# cslr_dev register map
Vendor: Texas Instruments
Peripheral module from a debugger description file.
Registers are 32-bit, access not given, reset 0x0 unless marked. A register's access mark holds for its fields unless they carry their own. Offsets are as the file gives them; lines under a group give offsets from that group; [hi:lo] are bit positions; {n}, {i} and the like mark numbered series; 'fields as' and 'values as' point back to an identical list; <NAME> marks a mode.

## DEV — Device Registers on the SOC
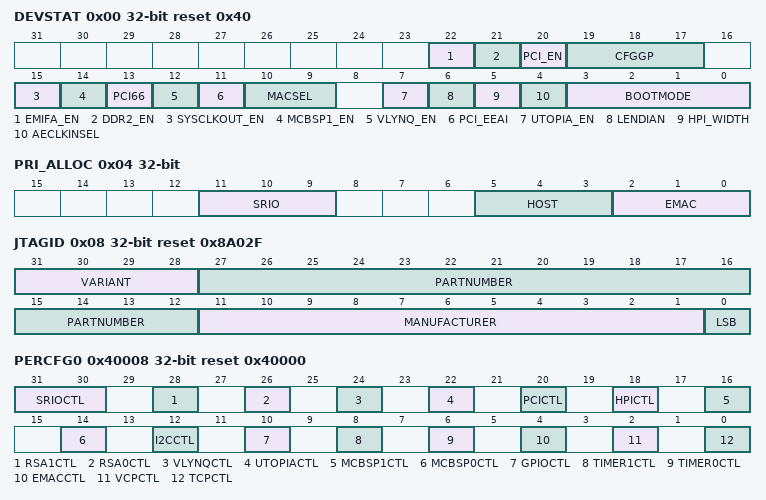
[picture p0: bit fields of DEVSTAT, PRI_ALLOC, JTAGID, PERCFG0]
0x00 DEVSTAT reset 0x40 — Device Status Register
  [22] EMIFA_EN ro — EMIFA Enable Status
    0=DISABLE; 1=ENABLE
  [21] DDR2_EN ro — DDR2 Enable Status
    0=DISABLE; 1=ENABLE
  [20] PCI_EN ro — PCI Enable Status
    0=HPI (HPI is enabled); 1=PCI (PCI is enabled)
  [19:17] CFGGP ro — Used as general purpose input for configuration
  [15] SYSCLKOUT_EN ro — Sysclkout enable status
    0=GP1 (GP[1] pin function of the SYSCLK4/GP[1] pin enabled (default).); 1=SYSCLK4 (SYSCLK4 pin function of the SYSCLK4/GP[1] pin enabled.)
  [14] MCBSP1_EN ro — McBSP1 enable status bits
    0=GPIO (GPIO pin functions enabled (default).); 1=MCBSP_1 (McBSP1 pin functions enabled.)
  [13] PCI66 ro — PCI Frequency Selection (PCI66) status bit
    0=33MHZ (33 MHz operating frequency); 1=66MHZ (66MHz operating frequency)
  [12] VLYNQ_EN ro — VLYNQ Enable (VLYNQ_EN) status bit, Shows the status of whether the VLYNQ peripheral or McBSP1, McBSP0, GPIO peripherals are enabled/disabled.
    0=DISABLE (Vlynq disabled, Mcbsp0,Mcbsp1, gpio enabled); 1=ENABLE (Vlynq enabled, Mcbsp0,Mcbsp1, gpio disabled)
  [11] PCI_EEAI ro — PCI EEPROM Auto-Initialization (PCI_EEAI) status bit.Shows whether the PCI auto-initialization via external EEPROM is enabled/disabled.
    0=DISABLE (PCI auto-initialization through external EEPROM is disabled; the PCI peripheral uses the specified); 1=ENABLE (PCI auto-initialization through external EEPROM is enabled; the PCI peripheral is configured through external I2C EEPROM provided the PCI peripheral pin is enabled (PCI_EN = 1).)
  [10:9] MACSEL ro — MACSEL[1:0] EMAC Interface Select (MACSEL[1:0]) status bits. Shows which EMAC interface mode has been selected.
    0=MII (10/100 EMAC/MDIO with MII Interface); 1=RMII (10/100 EMAC/MDIO with RMII Interface); 2=GMII (10/100/1000 EMAC/MDIO with GMII Interface); 3=RGMII (10/100/1000 EMAC/MDIO with RGMII Mode Interface)
  [7] UTOPIA_EN ro — UTOPIA enable status bit
    0=DISABLE (UTOPIA disabled); 1=ENABLE (UTOPIA enabled)
  [6] LENDIAN ro — Device Endian Mode
    0=BE (System is operating in Big Endian Mode); 1=LE (System is operating in Little Endian Mode)
  [5] HPI_WIDTH ro — HPI bus width control bit
    0=16BIT (HPI operating in 16-bit mode); 1=32BIT (HPI operating in 32-bit mode)
  [4] AECLKINSEL ro — EMIFA input clock select
    0=AECLKIN; 1=SYSCLK3 (The SYSCLK3 clock rate is software selectable via the software PLL1 controller. By default, SYSCLK3 is selected as CPU/8 clock rate.)
  [3:0] BOOTMODE ro — Bootmode configuration bits
    0=NONE (No Boot); 1=HPI_PCI (HPI/PCI Boot); 2=EMIFA64BIT (EMIFA 64-bit fast boot); 4=EMIFA8BIT (EMIFA 8-bit ROM boot); 5=I2C (I2C boot); 6=UTOPIA (Utopia boot); 7=EMAC (Emac boot); 9=SRIO (Rapid I/O boot)
0x04 PRI_ALLOC — Priority Allocation Register
  [11:9] SRIO — SRIO Descriptor
  [5:3] HOST — Host Priority
  [2:0] EMAC — Emac Priority
0x08 JTAGID ro reset 0x8A02F — JTAG and BSDL Identification register
  [31:28] VARIANT, [27:12] PARTNUMBER, [11:1] MANUFACTURER, [0] LSB
0x40004 PERLOCK wo reset 0xF0F0F0F0 — Peripheral lock register
  [31:0] LOCKVAL — When programmed with 0xF0A0B00 allows one write to one of PERCFG0 16 SYSCLK2 cycles.
    0xF0A0B00=UNLOCK
0x40008 PERCFG0 reset 0x40000 — Peripheral Configuration register
  [31:30] SRIOCTL wo — Mode control for SRIO
    0=DISABLE; 3=ENABLE
  [28] RSA1CTL wo — Mode control for RSA1
    0=DISABLE; 1=ENABLE
  [26] RSA0CTL wo — Mode control for RSA0
    0=DISABLE; 1=ENABLE
  [24] VLYNQCTL wo — Mode control for VLYNQ
    0=DISABLE; 1=ENABLE
  [22] UTOPIACTL wo — Mode control for UTOPIA
    0=DISABLE; 1=ENABLE
  [20] PCICTL wo — Mode control for PCI
    0=DISABLE; 1=ENABLE
  [18] HPICTL wo — Mode control for HPI
    0=DISABLE; 1=ENABLE
  [16] MCBSP1CTL wo — Mode control for MCBSP1
    0=DISABLE; 1=ENABLE
  [14] MCBSP0CTL wo — Mode control for MCBSP0
    0=DISABLE; 1=ENABLE
  [12] I2CCTL wo — Mode control for I2C
    0=DISABLE; 1=ENABLE
  [10] GPIOCTL wo — Mode control for GPIO
    0=DISABLE; 1=ENABLE
  [8] TIMER1CTL wo — Mode control for Timer1
    0=DISABLE; 1=ENABLE
  [6] TIMER0CTL wo — Mode control for Timer0
    0=DISABLE; 1=ENABLE
  [4] EMACCTL wo — Mode control for EMAC
    0=DISABLE; 1=ENABLE
  [2] VCPCTL wo — Mode control for VCP
    0=DISABLE; 1=ENABLE
  [0] TCPCTL wo — Mode control for TCP
    0=DISABLE; 1=ENABLE
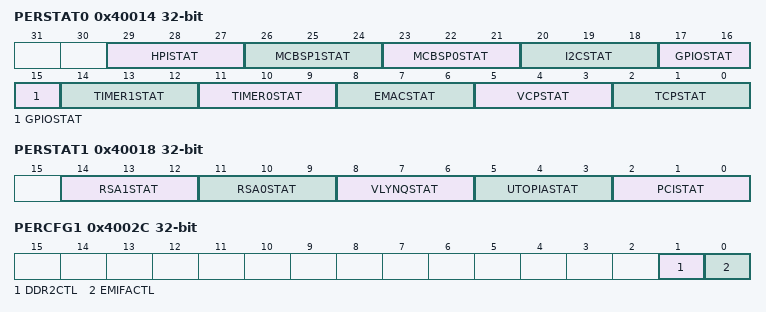
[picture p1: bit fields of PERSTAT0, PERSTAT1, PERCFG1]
0x40014 PERSTAT0 — Peripheral Status 0
  [all] fields
    3=STATIC_PDN (Static Powerdown); 0=DISABLE; 1=ENABLE; 4=DISABLE_IN_PROGRESS; 5=ENABLE_IN_PROGRESS
  [29:27] HPISTAT ro — HPI Status
  [26:24] MCBSP1STAT ro — MCBSP1 Status
  [23:21] MCBSP0STAT ro — MCBSP0 Status
  [20:18] I2CSTAT ro — I2C Status
  [17:15] GPIOSTAT ro — GPIO Status
  [14:12] TIMER1STAT ro — Timer 1 Status
  [11:9] TIMER0STAT ro — Timer 0 Status
  [8:6] EMACSTAT ro — EMAC Status
  [5:3] VCPSTAT ro — VCP Status
  [2:0] TCPSTAT ro — TCP Status
0x40018 PERSTAT1 — Peripheral Status 1
  [all] fields
    values as the fields of PERSTAT0
  [14:12] RSA1STAT ro — RSA 1 Status
  [11:9] RSA0STAT ro — RSA 0 Status
  [8:6] VLYNQSTAT ro — Vlynq Status
  [5:3] UTOPIASTAT ro — Utopia Status
  [2:0] PCISTAT ro — PCI Status
0x4002C PERCFG1 — Peripheral configuration 1
  [1] DDR2CTL wo — This bit gates of clock to DDR2. Once programmed with 1 cannot be programmed to 0
    1=ENABLE; 0=DISABLE
  [0] EMIFACTL wo — This bit gates of clock to EMIFA. Once programmed with 1 cannot be programmed to 0
    1=ENABLE; 0=DISABLE
0x40054 EMUBUFPDN — Emulation Buffer Powerdown
  [0] EMUCTL rw — Powerdown signal for the emulation buffer
    0=ENABLE; 1=DISABLE
